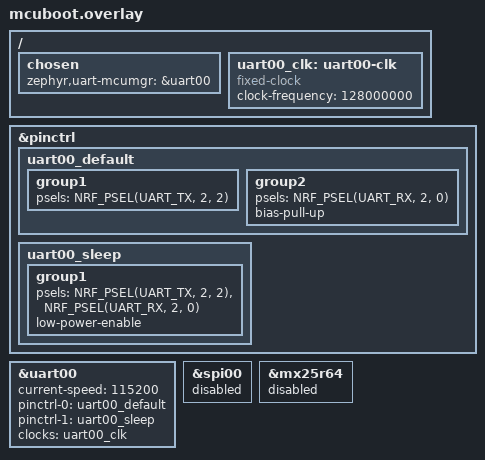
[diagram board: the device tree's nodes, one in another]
/*
 * FCK module (KDFCK001) - nRF54L15 U701 devicetree for the DFU application.
 *
 * The only host link is the UART on P2.02 (TX) / P2.00 (RX), which reach the ESP32-P4
 * through J401.12 / J401.14. SMP (mcumgr) runs over this UART, so it is the mcumgr
 * transport (zephyr,uart-mcumgr), not a console. P2 pins are in the fast domain -> UARTE00.
 *
 * Two board-specific fixes:
 *  - spi00 disabled: SERIAL00 @0x4a000 is exposed as spi00 AND uart00; only one may be on.
 *  - uart00_clk fixed-clock: UARTE00's PCLK is 128 MHz but BAUDRATE constants are 16 MHz-
 *    based, so without a `clocks` phandle 115200 becomes 921600 (8x). This gives clean 115200.
 */

/ {
	chosen {
		zephyr,uart-mcumgr = &uart00;
	};

	uart00_clk: uart00-clk {
		compatible = "fixed-clock";
		#clock-cells = <0>;
		clock-frequency = <128000000>;
	};
};

&pinctrl {
	uart00_default: uart00_default {
		group1 {
			psels = <NRF_PSEL(UART_TX, 2, 2)>;
		};
		group2 {
			psels = <NRF_PSEL(UART_RX, 2, 0)>;
			bias-pull-up;
		};
	};

	uart00_sleep: uart00_sleep {
		group1 {
			psels = <NRF_PSEL(UART_TX, 2, 2)>,
				<NRF_PSEL(UART_RX, 2, 0)>;
			low-power-enable;
		};
	};
};

&uart00 {
	status = "okay";
	current-speed = <115200>;
	pinctrl-0 = <&uart00_default>;
	pinctrl-1 = <&uart00_sleep>;
	pinctrl-names = "default", "sleep";
	clocks = <&uart00_clk>;
};

&spi00 {
	status = "disabled";
};

/*
 * The DK devicetree hangs an external flash (MX25R64) off spi00. On the FCK that block is
 * the UART instead and there is no external flash, so disabling spi00 leaves the mx25r64 node
 * parentless (build error: __device_dts_ord_xxx undeclared in spi_nor.c). Disable it too.
 * Code/slots live in internal RRAM (zephyr,flash = &cpuapp_rram), so nothing depends on it.
 */
&mx25r64 {
	status = "disabled";
};
